# CH585SFR register map
Vendor: WCH Ltd.; Series: CH58x; File version: 1.1
CPU: RISC-V r0p0, little endian, no MPU, no FPU, 2 interrupt priority bits
Registers are 8-bit, read-write, reset 0x0 unless marked. A register's access mark holds for its fields unless they carry their own. Offsets are from the block's base; [hi:lo] are bit positions.

## TMR1 — Timer1 register
Base 0x40002400
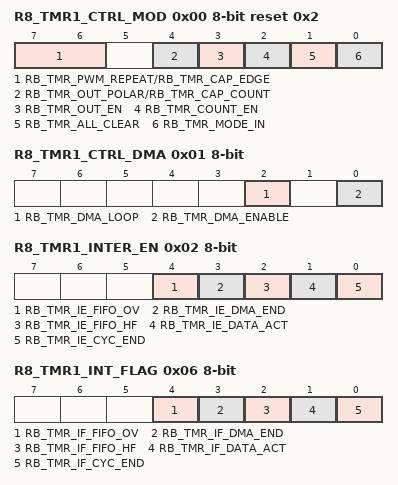
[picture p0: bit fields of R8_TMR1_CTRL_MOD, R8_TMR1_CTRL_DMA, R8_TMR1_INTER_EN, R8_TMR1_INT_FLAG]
0x00 R8_TMR1_CTRL_MOD reset 0x2 — RW, TMR1 mode control
  [7:6] RB_TMR_PWM_REPEAT/RB_TMR_CAP_EDGE — RW, timer PWM repeat mode: 00=1, 01=4, 10=8, 11-16;RW, timer capture edge mode: 00=disable, 01=edge change, 10=fall to fall, 11-rise to rise
  [4] RB_TMR_OUT_POLAR/RB_TMR_CAP_COUNT — RW, timer PWM output polarity: 0=default low and high action, 1=default high and low action;RW, count sub-mode if RB_TMR_MODE_IN=1: 0=capture, 1=count
  [3] RB_TMR_OUT_EN — RW, timer output enable
  [2] RB_TMR_COUNT_EN — RW, timer count enable
  [1] RB_TMR_ALL_CLEAR — RW, force clear timer FIFO and count
  [0] RB_TMR_MODE_IN — RW, timer in mode: 0=timer/PWM, 1=capture/count
0x01 R8_TMR1_CTRL_DMA — RW, TMR1 DMA control
  [2] RB_TMR_DMA_LOOP — RW, timer1 DMA address loop enable
  [0] RB_TMR_DMA_ENABLE — RW, timer1 DMA enable
0x02 R8_TMR1_INTER_EN — RW, TMR1 interrupt enable
  [4] RB_TMR_IE_FIFO_OV — RW, enable interrupt for timer FIFO overflow
  [3] RB_TMR_IE_DMA_END — RW, enable interrupt for timer1 DMA completion
  [2] RB_TMR_IE_FIFO_HF — RW, enable interrupt for timer FIFO half (capture fifo >=4 or PWM fifo less than 3)
  [1] RB_TMR_IE_DATA_ACT — RW, enable interrupt for timer capture input action or PWM trigger
  [0] RB_TMR_IE_CYC_END — RW, enable interrupt for timer capture count timeout or PWM cycle end
0x06 R8_TMR1_INT_FLAG — RW1, TMR1 interrupt flag
  [4] RB_TMR_IF_FIFO_OV — RW1, interrupt flag for timer FIFO overflow
  [3] RB_TMR_IF_DMA_END — RW1, interrupt flag for timer1 DMA completion
  [2] RB_TMR_IF_FIFO_HF — RW1, interrupt flag for timer FIFO half (capture fifo >=4 or PWM fifo less than 3
  [1] RB_TMR_IF_DATA_ACT — RW1, interrupt flag for timer capture input action or PWM trigger
  [0] RB_TMR_IF_CYC_END — RW1, interrupt flag for timer capture count timeout or PWM cycle end
0x07 R8_TMR1_FIFO_COUNT ro reset not defined — RO, TMR1 FIFO count status
  [3:0] R8_TMR1_FIFO_COUNT — RW1, TMR1 FIFO count status
0x08 R32_TMR1_COUNT 32-bit ro reset not defined — RO, TMR1 current count
  [25:0] R32_TMR1_COUNT — RW1,TMR1 current count
0x0C R32_TMR1_CNT_END 32-bit reset not defined — RW, TMR1 end count value, only low 26 bit
  [31:0] R32_TMR1_CNT_END — RW1,TMR1 end count value,
0x10 R32_TMR1_FIFO 32-bit ro reset not defined — RO, TMR1 FIFO register, only low 26 bit
  [31:0] R32_TMR1_FIFO — RW1,TMR1 FIFO register
0x14 R16_TMR1_DMA_NOW 16-bit ro reset not defined — RO, TMR1 DMA current address
  [16:2] R16_TMR1_DMA_NOW — RO,DMA data buffer current address
0x18 R16_TMR1_DMA_BEG 16-bit reset not defined — RW, TMR1 DMA begin address
  [16:2] R16_TMR1_DMA_BEG — RW,TMR1 DMA data buffer start address
0x1C R16_TMR1_DMA_END 16-bit reset not defined — RW, TMR1 DMA end address
  [16:2] R16_TMR1_DMA_END — RW,DMA data buffer end address

## TMR2 — Timer2 register
Base 0x40002800
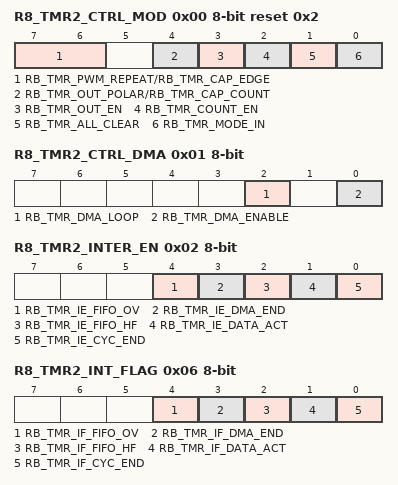
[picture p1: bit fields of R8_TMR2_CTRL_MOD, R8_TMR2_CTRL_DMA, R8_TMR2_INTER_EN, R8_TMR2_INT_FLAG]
0x00 R8_TMR2_CTRL_MOD reset 0x2 — RW, TMR2 mode control
  [7:6] RB_TMR_PWM_REPEAT/RB_TMR_CAP_EDGE — RW, timer PWM repeat mode: 00=1, 01=4, 10=8, 11-16;RW, timer capture edge mode: 00=disable, 01=edge change, 10=fall to fall, 11-rise to rise
  [4] RB_TMR_OUT_POLAR/RB_TMR_CAP_COUNT — RW, timer PWM output polarity: 0=default low and high action, 1=default high and low action;RW, count sub-mode if RB_TMR_MODE_IN=1: 0=capture, 1=count
  [3] RB_TMR_OUT_EN — RW, timer output enable
  [2] RB_TMR_COUNT_EN — RW, timer count enable
  [1] RB_TMR_ALL_CLEAR — RW, force clear timer FIFO and count
  [0] RB_TMR_MODE_IN — RW, timer in mode: 0=timer_PWM, 1=capture_count
0x01 R8_TMR2_CTRL_DMA — RW, TMR2 DMA control
  [2] RB_TMR_DMA_LOOP — RW, timer2 DMA address loop enable
  [0] RB_TMR_DMA_ENABLE — RW, timer2 DMA enable
0x02 R8_TMR2_INTER_EN — RW, TMR2 interrupt enable
  [4] RB_TMR_IE_FIFO_OV — RW, enable interrupt for timer FIFO overflow
  [3] RB_TMR_IE_DMA_END — RW, enable interrupt for timer1/2 DMA completion
  [2] RB_TMR_IE_FIFO_HF — RW, enable interrupt for timer FIFO half (capture fifo >=4 or PWM fifo less than 3)
  [1] RB_TMR_IE_DATA_ACT — RW, enable interrupt for timer capture input action or PWM trigger
  [0] RB_TMR_IE_CYC_END — RW, enable interrupt for timer capture count timeout or PWM cycle end
0x06 R8_TMR2_INT_FLAG — RW1, TMR2 interrupt flag
  [4] RB_TMR_IF_FIFO_OV — RW1, interrupt flag for timer FIFO overflow
  [3] RB_TMR_IF_DMA_END — RW1, interrupt flag for timer2 DMA completion
  [2] RB_TMR_IF_FIFO_HF — RW1, interrupt flag for timer FIFO half (capture fifo >=4 or PWM fifo less than 3
  [1] RB_TMR_IF_DATA_ACT — RW1, interrupt flag for timer capture input action or PWM trigger
  [0] RB_TMR_IF_CYC_END — RW1, interrupt flag for timer capture count timeout or PWM cycle end
0x07 R8_TMR2_FIFO_COUNT ro reset not defined — RO, TMR2 FIFO count status
  [3:0] R8_TMR2_FIFO_COUNT — RW, TMR2 FIFO count status
0x08 R32_TMR2_COUNT 32-bit ro reset not defined — RO, TMR2 current count
  [25:0] R32_TMR2_COUNT — RW, TMR2 current count
0x0C R32_TMR2_CNT_END 32-bit reset not defined — RW, TMR2 end count value, only low 26 bit
  [31:0] R32_TMR2_COUNT — RW, TMR2 current count
0x10 R32_TMR2_FIFO 32-bit reset not defined — RO, TMR2 FIFO register, only low 26 bit
  [31:0] R32_TMR2_FIFO — RW, TMR2 current count
0x14 R16_TMR2_DMA_NOW 16-bit ro reset not defined — RO, TMR2 DMA current address
  [16:2] R16_TMR2_DMA_NOW — RO, DMA data buffer current address
0x18 R16_TMR2_DMA_BEG 16-bit reset not defined — RW, TMR2 DMA begin address
  [16:2] R16_TMR2_DMA_BEG — RW, TMR2 DMA data buffer start address
0x1C R16_TMR2_DMA_END 16-bit reset not defined — RW, TMR2 DMA end address
  [16:2] R16_TMR2_DMA_END
